# SAM9X75D5MN0 device description
Architecture: ARM926EJ-S; Family: SAM9; Series: SAM9X7
Registers are 32-bit, read-write, reset 0x0 unless marked. A register's access mark holds for its fields unless they carry their own. Offsets are from the block's base; [hi:lo] are bit positions; {n}, {i} and the like mark numbered series; 'fields as' and 'values as' point back to an identical list.

## I2SMCC — Inter-IC Sound Multi Channel Controller
Instances: I2SMCC 0xF001C000
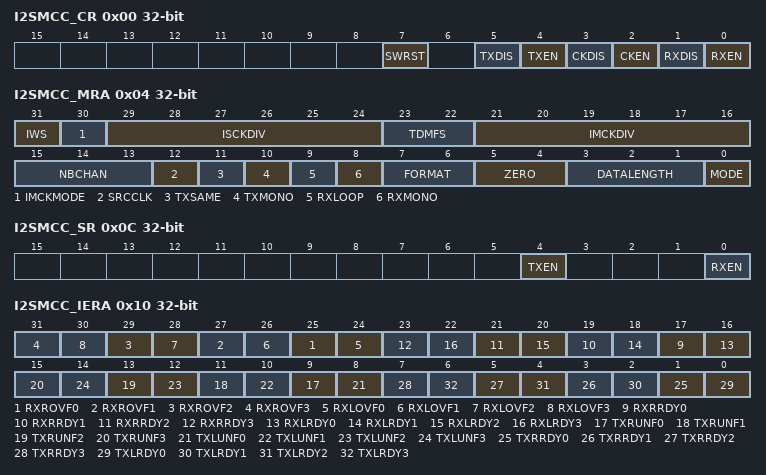
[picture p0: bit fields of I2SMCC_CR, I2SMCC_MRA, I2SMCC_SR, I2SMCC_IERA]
0x00 I2SMCC_CR wo reset not defined — Control Register
  [7] SWRST — Software Reset
    0=No effect; 1=Resets all the registers in the I2SMCC. The I2SMCC is disabled after the reset.
  [5] TXDIS — Transmitter Disable
    0=No effect; 1=Disables the I2SMCC transmitter. Bit I2SMCC_SR.TXEN is cleared when the Transmitter is stopped.
  [4] TXEN — Transmitter Enable
    0=No effect; 1=Enables the I2SMCC transmitter, if TXDIS is not '1'. Bit I2SMCC_SR.TXEN is set when the Transmitter is started.
  [3] CKDIS — Clocks Disable
    0=No effect; 1=Disables the I2SMCC clock generation
  [2] CKEN — Clocks Enable
    0=No effect; 1=Enables the I2SMCC clock generation, if CKDIS is not '1'
  [1] RXDIS — Receiver Disable
    0=No effect; 1=Disables the I2SMCC receiver. Bit I2SMCC_SR.RXEN is cleared when the receiver is stopped.
  [0] RXEN — Receiver Enable
    0=No effect; 1=Enables the I2SMCC receiver, if RXDIS is not '1'. Bit I2SMCC_SR.RXEN is set when the receiver is activated.
0x04 I2SMCC_MRA — Mode Register A
  [31] IWS — I2SMCC_WS Slot Length
    0=I2SMCC_WS slot is 32 bits long for DATALENGTH = 18/20/24 bits; 1=I2SMCC_WS slot is 24 bits long for DATALENGTH = 18/20/24 bits
  [30] IMCKMODE — Host Clock Mode
    0=No host clock generated; 1=Host clock generated
  [29:24] ISCKDIV — Selected Clock to I2SMCC Serial Clock Ratio
  [23:22] TDMFS — TDM Frame Synchronization
    0=SLOT (I2SMCC_WS pulse is high for one time slot at beginning of frame.); 1=HALF (I2SMCC_WS pulse is high for half the time slots at beginning of frame.); 2=BIT (I2SMCC_WS pulse is high for one bit period at beginning of frame, i.e., one I2SMCC_CK period.)
  [21:16] IMCKDIV — Selected Clock to I2SMCC Host Clock Ratio
  [15:13] NBCHAN — Number of TDM Channels-1
  [12] SRCCLK — Source Clock Selection
    0=The Peripheral clock is selected as source clock for I2SMCC_MCK/WS/CK pins; 1=The PMC.GCLKx clock is selected as source clock (I2SMCC_MCK/WS/CK rate can be independent of system bus clock)
  [11] TXSAME — Transmit Data when Underrun
    0='0' is transmitted when underrun; 1=Previous sample transmitted when underrun
  [10] TXMONO — Transmit Mono
    0=Stereo; 1=Mono, with left audio samples duplicated to right audio channel by the I2SMCC
  [9] RXLOOP — Loop-back Test Mode
    0=Normal mode; 1=I2SMCC_DOUT output of I2SMCC are internally connected to I2SMCC_DIN input
  [8] RXMONO — Receive Mono
    values as TXMONO
  [7:6] FORMAT — Data Format
    0=I2S (I2S format, stereo with I2SMCC_WS low for left channel, and MSB of sample starting one I2SMCC_CK period after I2SMCC_WS edge.); 1=LJ (Left-justified format, stereo with I2SMCC_WS high for left channel, and MSB of sample starting on I2SMCC_WS edge.); 2=TDM (TDM format, with (NBCHAN + 1) channels, I2SMCC_WS high at beginning of first channel, and MSB of sample starting one I2SMCC_CK period after I2SMCC_WS edge.); 3=TDMLJ (TDM format, left-justified, with (NBCHAN + 1) channels, I2SMCC_WS high at beginning of first channel, and MSB of sample starting on I2SMCC_WS edge.)
  [5:4] ZERO — Must always be written to 0.
  [3:1] DATALENGTH — Data Word Length
    0=32_BITS (Data length is set to 32 bits.); 1=24_BITS (Data length is set to 24 bits.); 2=20_BITS (Data length is set to 20 bits.); 3=18_BITS (Data length is set to 18 bits.); 4=16_BITS (Data length is set to 16 bits.); 5=16_BITS_COMPACT (Data length is set to 16-bit compact stereo. Left sample in bits [15:0] and right sample in bits [31:16] of same word.); 6=8_BITS (Data length is set to 8 bits.); 7=8_BITS_COMPACT (Data length is set to 8-bit compact stereo. Left sample in bits [7:0] and right sample in bits [15:8] of the same word.)
  [0] MODE — Inter-IC Sound Multi Channel Controller Mode
    0=SLAVE (Client mode. I2SMCC_CK and I2SMCC_WS pin inputs used as bit clock and word select/frame synchronization.); 1=MASTER (Host mode. Bit clock and word select/frame synchronization generated by I2SMCC from Peripheral Clock or GCLK if I2SMCC_MCK/WS/CK rates must be independent of system bus clock (See I2SMCC_MR.SRCCLK) and output to I2SMCC_CK and I2SMCC_WS pins. MCK is output as host clock on I2SMCC_MCK if I2SMCC_MRA.IMCKMODE is set.)
0x08 I2SMCC_MRB — Mode Register B
  [9:8] DMACHUNK — DMA Chunk Size
    0=1_WORD (A DMA transfer request is issued when at least 1 word is empty in the FIFO.); 1=2_WORDS (A DMA transfer request is issued when at least 2 words are empty in the FIFO.); 2=4_WORDS (A DMA transfer request is issued when at least 4 words are empty in the FIFO. Limitations exist when operating in Mono or TDM. See Table 7-7 "TX DMA Chunk Configurations" and Table 7-8 "RX DMA Chunk Configurations".); 3=8_WORDS (A DMA transfer request is issued when at least 8 words are empty in the FIFO. Limitations exist when operating in Mono or TDM. See Table 7-7 "TX DMA Chunk Configurations" and Table 7-8 "RX DMA Chunk Configurations".)
0x0C I2SMCC_SR ro — Status Register
  [4] TXEN — Transmitter Enabled
    0=Cleared when the transmitter is disabled, following a I2SMCC_CR.TXDIS or I2SMCC_CR.SWRST request; 1=Set when the transmitter is enabled, following a I2SMCC_CR.TXEN request
  [0] RXEN — Receiver Enabled
    0=Cleared when the receiver is disabled, following a RXDIS or SWRST request in I2SMCC_CR; 1=Set when the receiver is enabled, following a RXEN request in I2SMCC_CR
0x10 I2SMCC_IERA wo reset not defined (atomic set of I2SMCC_IMRA) — Interrupt Enable Register A
  [2n+25] RXROVF{n} (n=0..3) — I2S Receive Right {n} (x=0 only) or TDM Channel [2x]+1 Overrun Interrupt Enable
  [2n+24] RXLOVF{n} (n=0..3) — I2S Receive Left {n} (x=0 only) or TDM Channel 2x Overrun Interrupt Enable
  [2n+17] RXRRDY{n} (n=0..3) — I2S Receive Right {n} (x=0 only) or TDM Channel [2x]+1 Ready Interrupt Enable
  [2n+16] RXLRDY{n} (n=0..3) — I2S Receive Left {n} (x=0 only) or TDM Channel 2x Ready Interrupt Enable
  [2n+9] TXRUNF{n} (n=0..3) — I2S Transmit Right {n} (x=0 only) or TDM Channel [2x]+1 Underrun Interrupt Enable
  [2n+8] TXLUNF{n} (n=0..3) — I2S Transmit Left {n} (x=0 only) or TDM Channel 2x Underrun Interrupt Enable
  [2n+1] TXRRDY{n} (n=0..3) — I2S Transmit Right {n} (x=0 only) or TDM Channel [2x]+1 Ready Interrupt Enable
  [2n] TXLRDY{n} (n=0..3) — I2S Transmit Left {n} (x=0 only) or TDM Channel 2x Ready Interrupt Enable
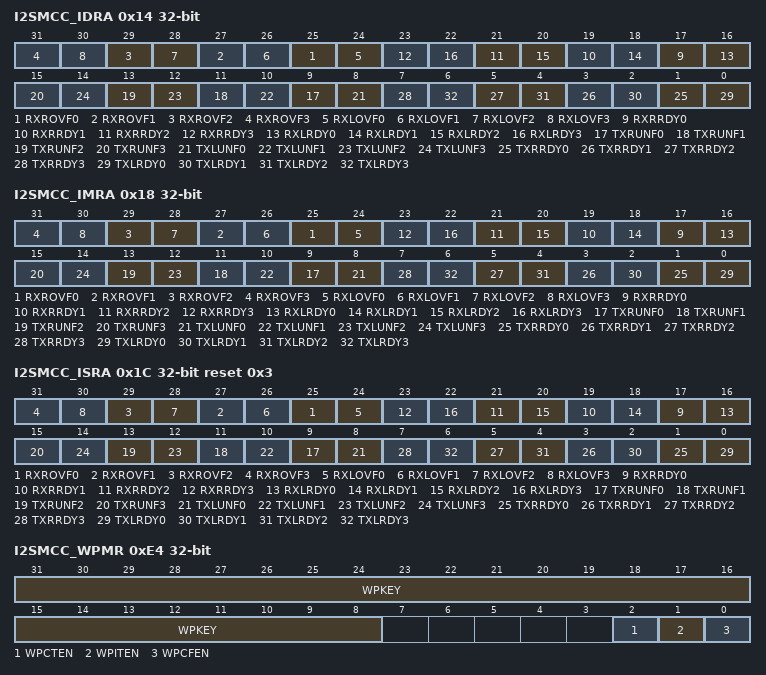
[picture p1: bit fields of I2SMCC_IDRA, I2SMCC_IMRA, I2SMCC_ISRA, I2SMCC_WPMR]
0x14 I2SMCC_IDRA wo reset not defined (atomic clear of I2SMCC_IMRA) — Interrupt Disable Register A
  [2n+25] RXROVF{n} (n=0..3) — I2S Receive Right {n} (x=0 only) or TDM Channel [2x]+1 Overrun Interrupt Disable
  [2n+24] RXLOVF{n} (n=0..3) — I2S Receive Left {n} (x=0 only) or TDM Channel 2x Overrun Interrupt Disable
  [2n+17] RXRRDY{n} (n=0..3) — I2S Receive Right {n} (x=0 only) or TDM Channel [2x]+1 Ready Interrupt Disable
  [2n+16] RXLRDY{n} (n=0..3) — I2S Receive Left {n} (x=0 only) or TDM Channel 2x Ready Interrupt Disable
  [2n+9] TXRUNF{n} (n=0..3) — I2S Transmit Right {n} (x=0 only) or TDM Channel [2x]+1 Underrun Interrupt Disable
  [2n+8] TXLUNF{n} (n=0..3) — I2S Transmit Left {n} (x=0 only) or TDM Channel 2x Underrun Interrupt Disable
  [2n+1] TXRRDY{n} (n=0..3) — I2S Transmit Right {n} (x=0 only) or TDM Channel [2x]+1 Ready Interrupt Disable
  [2n] TXLRDY{n} (n=0..3) — I2S Transmit Left {n} (x=0 only) or TDM Channel 2x Ready Interrupt Disable
0x18 I2SMCC_IMRA ro — Interrupt Mask Register A
  [2n+25] RXROVF{n} (n=0..3) — I2S Receive Right {n} (x=0 only) or TDM Channel [2x]+1 Overrun Interrupt Mask
  [2n+24] RXLOVF{n} (n=0..3) — I2S Receive Left {n} (x=0 only) or TDM Channel 2x Overrun Interrupt Mask
  [2n+17] RXRRDY{n} (n=0..3) — I2S Receive Right {n} (x=0 only) or TDM Channel [2x]+1 Ready Interrupt Mask
  [2n+16] RXLRDY{n} (n=0..3) — I2S Receive Left {n} (x=0 only) or TDM Channel 2x Ready Interrupt Mask
  [2n+9] TXRUNF{n} (n=0..3) — I2S Transmit Right {n} (x=0 only) or TDM Channel [2x]+1 Underrun Interrupt Mask
  [2n+8] TXLUNF{n} (n=0..3) — I2S Transmit Left {n} (x=0 only) or TDM Channel 2x Underrun Interrupt Mask
  [2n+1] TXRRDY{n} (n=0..3) — I2S Transmit Right {n} (x=0 only) or TDM Channel [2x]+1 Ready Interrupt Mask
  [2n] TXLRDY{n} (n=0..3) — I2S Transmit Left {n} (x=0 only) or TDM Channel 2x Ready Interrupt Mask
0x1C I2SMCC_ISRA ro reset 0x3 — Interrupt Status Register A
  [2n+25] RXROVF{n} (n=0..3) — I2S Receive Right {n} (x=0 only) or TDM Channel [2x]+1 Overrun Flag (Cleared on read)
    0=Cleared when I2SMCC_ISRA is read; 1=Set when an overrun error occurs in I2SMCC_RHR
  [2n+24] RXLOVF{n} (n=0..3) — I2S Receive Left {n} (x=0 only) or TDM Channel 2x Overrun Flag (Cleared on read)
    values as RXROVF0
  [2n+17] RXRRDY{n} (n=0..3) — I2S Receive Right {n} (x=0 only) or TDM Channel [2x]+1 Ready Flag (Cleared by reading I2SMCC_RHR)
    0=Cleared when a predefined number of read accesses is performed in I2SMCC_RHR. The predefined number depends on the configuration of I2SMCC_MRA.WIRECFG / FORMAT and varies from 1 to 8.; 1=Set when received data is available in I2SMCC_RHR
  [2n+16] RXLRDY{n} (n=0..3) — I2S Receive Left {n} (x=0 only) or TDM Channel 2x Ready Flag (Cleared by reading I2SMCC_RHR)
    0=Cleared when a predefined number of read accesses are performed in I2SMCC_RHR. The predefined number depends on the configuration of I2SMCC_MRA.WIRECFG / FORMAT and varies from 1 to 7.; 1=Set when received data is available in I2SMCC_RHR
  [2n+9] TXRUNF{n} (n=0..3) — I2S Transmit Right {n} (x=0 only) or TDM Channel [2x]+1 Underrun Flag (Cleared on read)
    0=Cleared when the I2SMCC_ISRA is read; 1=Set when an underrun error occurs in I2SMCC_THR
  [2n+8] TXLUNF{n} (n=0..3) — I2S Transmit Left {n} (x=0 only) or TDM Channel 2x Underrun (Cleared on read)
    0=Cleared when I2SMCC_ISRA is read; 1=Set when an underrun error occurs in I2SMCC_THR
  [2n+1] TXRRDY{n} (n=0..3) — I2S Transmit Right {n} (x=0 only) or TDM Channel [2x]+1 Ready Flag (Cleared by writing I2SMCC_THR)
    0=Cleared when a predefined number of write accesses are performed in I2SMCC_THR. The predefined number depends on the configuration of I2SMCC_MRA.WIRECFG / FORMAT and varies from 1 to 8.; 1=Set when I2SMCC_THR is empty
  [2n] TXLRDY{n} (n=0..3) — I2S Transmit Left {n} (x=0 only) or TDM Channel 2x Ready Flag (Cleared by writing I2SMCC_THR)
    0=Cleared when a predefined number of write accesses are performed in I2SMCC_THR. The predefined number depends on the configuration of I2SMCC_MRA.WIRECFG / FORMAT and varies from 1 to 7.; 1=Set when I2SMCC_THR is empty
0x20 I2SMCC_IERB wo reset not defined (atomic set of I2SMCC_IMRB) — Interrupt Enable Register B
  [0] WERR — Write Error Interrupt Enable
0x24 I2SMCC_IDRB wo reset not defined (atomic clear of I2SMCC_IMRB) — Interrupt Disable Register B
  [0] WERR — Write Error Interrupt Disable
0x28 I2SMCC_IMRB ro — Interrupt Mask Register B
  [0] WERR — Write Error Interrupt Enable
0x2C I2SMCC_ISRB ro — Interrupt Status Register B
  [0] WERR — Write Error Flag (cleared on read)
    0=Cleared when I2SMCC_ISRB is read; 1=Set when an error occurs in the I2SMCC_WPSR. Refer to I2SMCC_WPSR for details on the type of error.
0x30 I2SMCC_RHR ro — Receiver Holding Register
0x34 I2SMCC_THR wo reset not defined — Transmitter Holding Register
0xE4 I2SMCC_WPMR — Write Protection Mode Register
  [31:8] WPKEY — Write Protection Key
    0x493253=PASSWD (Writing any other value in this field aborts the write operation. Always reads as 0.)
  [2] WPCTEN — Write Protection Control Enable
    0=Disables the write protection of the control if WPKEY matches to 0x493253 (I2S in ASCII); 1=Enables the write protection of the control if WPKEY matches to 0x493253 (I2S in ASCII)
  [1] WPITEN — Write Protection Interrupt Enable
    0=Disables the write protection of the interruption if WPKEY matches to 0x493253 (I2S in ASCII); 1=Enables the write protection of the interruption if WPKEY matches to 0x493253 (I2S in ASCII)
  [0] WPCFEN — Write Protection Configuration Enable
    0=Disables the write protection of the configuration if WPKEY matches to 0x493253 (I2S in ASCII); 1=Enables the write protection of the configuration if WPKEY matches to 0x493253 (I2S in ASCII)
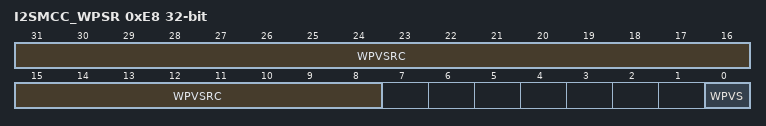
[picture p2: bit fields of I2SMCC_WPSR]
0xE8 I2SMCC_WPSR ro — Write Protection Status Register
  [31:8] WPVSRC — Write Protection Violation Source
  [0] WPVS — Write Protection Violation Status (cleared on read)
    0=No write protection violation has occurred since the last read of the I2SMCC_WPSR; 1=A write protection violation has occurred since the last read of the I2SMCC_WPSR. If this violation is an unauthorized attempt to write a protected register, the associated violation is reported into field WPVSRC.
